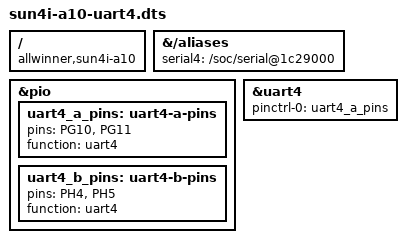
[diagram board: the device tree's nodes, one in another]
/dts-v1/;
/plugin/;

/ {
	compatible = "allwinner,sun4i-a10";

	fragment@0 {
		target-path = "/aliases";
		__overlay__ {
			serial4 = "/soc/serial@1c29000";
		};
	};

	fragment@1 {
		target = <&pio>;
		__overlay__ {
			uart4_a_pins: uart4-a-pins {
				pins = "PG10", "PG11";
				function = "uart4";
			};

			uart4_b_pins: uart4-b-pins {
				pins = "PH4", "PH5";
				function = "uart4";
			};
		};
	};

	fragment@2 {
		target = <&uart4>;
		 __overlay__ {
			pinctrl-names = "default";
			pinctrl-0 = <&uart4_a_pins>;
			status = "okay";
		};
	};
};
